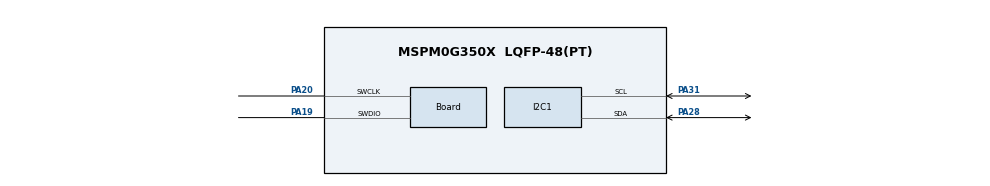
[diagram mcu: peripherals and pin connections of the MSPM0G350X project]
/**
 * @cliArgs --device "MSPM0G350X" --part "Default" --package "LQFP-48(PT)" --product "mspm0_sdk@2.04.00.06"
 * @versions {"tool":"1.22.0+3893"}
 */

/**
 * Import the modules used in this configuration.
 */
const GPIO    = scripting.addModule("/ti/driverlib/GPIO", {}, false);
const GPIO1   = GPIO.addInstance();
const I2C     = scripting.addModule("/ti/driverlib/I2C", {}, false);
const I2C1    = I2C.addInstance();
const SYSCTL  = scripting.addModule("/ti/driverlib/SYSCTL");
const SYSTICK = scripting.addModule("/ti/driverlib/SYSTICK");
const UART    = scripting.addModule("/ti/driverlib/UART", {}, false);
const UART1   = UART.addInstance();

/**
 * Write custom configuration values to the imported modules.
 */
GPIO1.$name                          = "BSL";
GPIO1.associatedPins[0].$name        = "PIN_18";
GPIO1.associatedPins[0].assignedPin  = "18";
GPIO1.associatedPins[0].assignedPort = "PORTA";

const Board                       = scripting.addModule("/ti/driverlib/Board", {}, false);
Board.peripheral.$assign          = "DEBUGSS";
Board.peripheral.swclkPin.$assign = "PA20";
Board.peripheral.swdioPin.$assign = "PA19";

I2C1.basicEnableController             = true;
I2C1.$name                             = "I2C_MPU6050";
I2C1.intController                     = ["ARBITRATION_LOST","EVENT1_DMA_DONE","EVENT2_DMA_DONE","NACK","RXFIFO_FULL","RXFIFO_TRIGGER","RX_DONE","START","STOP","TXFIFO_EMPTY","TXFIFO_TRIGGER","TX_DONE"];
I2C1.peripheral.sdaPin.$assign         = "PA28";
I2C1.peripheral.sclPin.$assign         = "PA31";
I2C1.sdaPinConfig.hideOutputInversion  = scripting.forceWrite(false);
I2C1.sdaPinConfig.onlyInternalResistor = scripting.forceWrite(false);
I2C1.sdaPinConfig.passedPeripheralType = scripting.forceWrite("Digital");
I2C1.sdaPinConfig.$name                = "ti_driverlib_gpio_GPIOPinGeneric2";
I2C1.sclPinConfig.hideOutputInversion  = scripting.forceWrite(false);
I2C1.sclPinConfig.onlyInternalResistor = scripting.forceWrite(false);
I2C1.sclPinConfig.passedPeripheralType = scripting.forceWrite("Digital");
I2C1.sclPinConfig.$name                = "ti_driverlib_gpio_GPIOPinGeneric3";

SYSCTL.forceDefaultClkConfig = true;
SYSCTL.peripheral.$assign    = "SYSCTL";

SYSTICK.periodEnable      = true;
SYSTICK.period            = 32000;
SYSTICK.interruptEnable   = true;
SYSTICK.systickEnable     = true;
SYSTICK.interruptPriority = "0";

UART1.enabledInterrupts                = ["RX"];
UART1.$name                            = "HC06";
UART1.peripheral.$assign               = "UART2";
UART1.txPinConfig.direction            = scripting.forceWrite("OUTPUT");
UART1.txPinConfig.hideOutputInversion  = scripting.forceWrite(false);
UART1.txPinConfig.onlyInternalResistor = scripting.forceWrite(false);
UART1.txPinConfig.passedPeripheralType = scripting.forceWrite("Digital");
UART1.txPinConfig.$name                = "ti_driverlib_gpio_GPIOPinGeneric0";
UART1.rxPinConfig.hideOutputInversion  = scripting.forceWrite(false);
UART1.rxPinConfig.onlyInternalResistor = scripting.forceWrite(false);
UART1.rxPinConfig.passedPeripheralType = scripting.forceWrite("Digital");
UART1.rxPinConfig.$name                = "ti_driverlib_gpio_GPIOPinGeneric1";

const ProjectConfig              = scripting.addModule("/ti/project_config/ProjectConfig", {}, false);
ProjectConfig.migrationCondition = true;

/**
 * Pinmux solution for unlocked pins/peripherals. This ensures that minor changes to the automatic solver in a future
 * version of the tool will not impact the pinmux you originally saw.  These lines can be completely deleted in order to
 * re-solve from scratch.
 */
GPIO1.associatedPins[0].pin.$suggestSolution = "PA18";
I2C1.peripheral.$suggestSolution             = "I2C0";
UART1.peripheral.rxPin.$suggestSolution      = "PA22";
UART1.peripheral.txPin.$suggestSolution      = "PA21";
